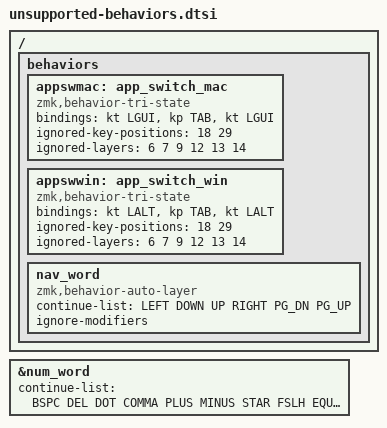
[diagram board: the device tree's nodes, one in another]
#include <behaviors/num_word.dtsi>
&num_word {
    // layer = <6>;  // replace NUM by the location of numbers layer
    continue-list = <BSPC DEL DOT COMMA PLUS MINUS STAR FSLH EQUAL LSHFT LEFT RIGHT UP DOWN TAB>;
};

/ {
    behaviors {
        appswmac: app_switch_mac {
            compatible = "zmk,behavior-tri-state";
            #binding-cells = <0>;
            bindings = <&kt LGUI>, <&kp TAB>, <&kt LGUI>;
            ignored-key-positions = <18 29>;// Ignort SHIFT key position so we can go back in the window list
            ignored-layers = <6 7 9 12 13 14>;
            // timeout-ms = <1000>;
        };
        appswwin: app_switch_win {
            compatible = "zmk,behavior-tri-state";
            #binding-cells = <0>;
            bindings = <&kt LALT>, <&kp TAB>, <&kt LALT>;
            ignored-key-positions = <18 29>;// Ignort SHIFT key position so we can go back in the window list
            ignored-layers = <6 7 9 12 13 14>;
            // timeout-ms = <1000>;
        };
        nav_word: nav_word {
            compatible = "zmk,behavior-auto-layer";
            #binding-cells = <1>;
            continue-list = <LEFT DOWN UP RIGHT PG_DN PG_UP>;
            ignore-modifiers;
        };
    };
};
